# MSS_SPI register map
Vendor: Texas Instruments
Peripheral module from a debugger description file (folder am273).
Registers are 32-bit, access per field, no defined reset value unless marked. A register's access mark holds for its fields unless they carry their own. Offsets are as the file gives them; lines under a group give offsets from that group; [hi:lo] are bit positions; {n}, {i} and the like mark numbered series; 'fields as' and 'values as' point back to an identical list; <NAME> marks a mode.

## MSS_SPI (part 1 of 3)
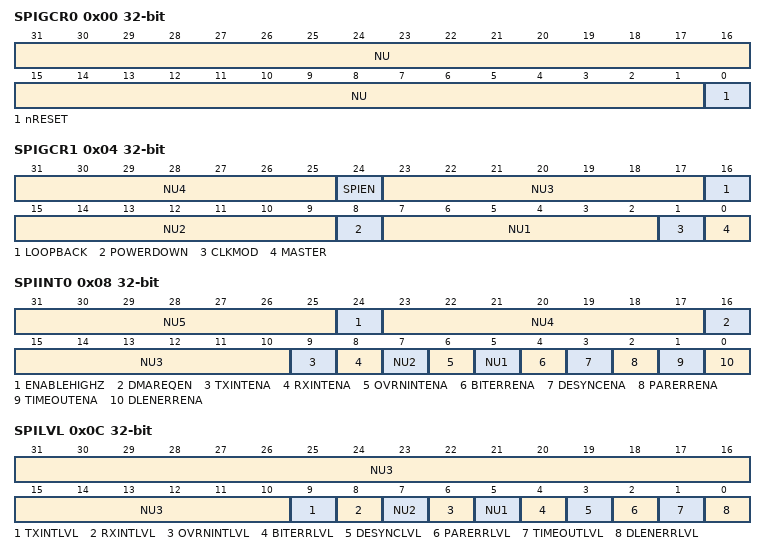
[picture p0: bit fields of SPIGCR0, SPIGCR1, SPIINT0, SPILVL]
0x00 SPIGCR0 — SPI / MibSPI Global Control Register 0
  [31:1] NU ro — Reserved, Reads return ‘0’ and writes have no effect.
  [0] nRESET rw — This is the local reset control for the module. This bit needs to be set to ‘1’ before any operation on SPI / MibSPI can be done. Only after setting this bit to ‘1’, the Auto Initialization of Multibuffer RAM starts. Clearing this bit to ‘0’ will result in all of the control and status register values to return to their default values. 0 = SPI / MibSPI is in reset state 1 = SPI / MibSPI is out of reset state.
0x04 SPIGCR1 — SPI / MibSPI Global control register 1
  [31:25] NU4 ro — Reserved. Reads return ‘0’ and writes have no effect.
  [24] SPIEN rw — SPI enable. This bit enables the SPI/MibSPI transfers. This bit must be set to 1 after all other SPI / MibSPI configuration bits have been written. When SPIEN bit is 0 or cleared to 0, the following SPI/MibSPI registers get forced to their default states (to ‘0’s except for RXEMPTY bit in SPIBUF): - Both TX & RX Shift Registers - The TXDATA fields of SPIDAT0 and SPIDAT1 registers - All the fields of SPIFLG register - Contents of SPIBUF & the internal RXBUF registers 0=SPI / MibSPI is not activated for transfers. 1=Activates SPI / MibSPI
  [23:17] NU3 ro — Reserved. Reads return ‘0’ and writes have no effect.
  [16] LOOPBACK rw — LOOP BACK. Internal loop-back test mode. The internal self-test option can be enabled by setting this bit. If the SPISIMO and SPISOMI pins are configured with SPI functionality, then the SPISIMO pin is internally connected to the SPISOMI pin. The transmit data is looped back as receive data and is stored in the receive field of the concerned buffer. Externally, during loop-back operation, the SPICLK pin outputs an inactive value and SPISOMI remains in high-impedance state. The SPI / MibSPI has to be initialized in master mode before the loop-back can be selected. If the SPI / MibSPI is initialized in slave mode or a data transfer is ongoing, errors may result. 1 =Internal loop-back test mode enabled. 0 =Internal loop-back test mode disabled. This loopback mode can be used only in Master mode. This automatically selects digital loopback path. When this Loopback mode is selected, CLKMOD bit should be set to ‘1’, meaning that SPICLK can only be internal.
  [15:9] NU2 ro — Reserved. Reads return ‘0’ and writes have no effect.
  [8] POWERDOWN rw — POWERDOWN. When active, the SPI / MibSPI state machines enter a powerdown state. 0=MibSPI in active mode 1=MibSPI in powerdown mode
  [7:2] NU1 ro — Reserved. Reads return ‘0’ and writes have no effect.
  [1] CLKMOD rw — CLKMOD. Clock mode Selects either an internal or external clock source. This bit also determines the I/O direction of the SPIENA and SPISCS[7:0] pins in functional mode. 0=Clock is external 1=Clock is internal
  [0] MASTER rw — MASTER: SPISIMO/SPISOMI pin direction determination. Determines the direction of the SPISIMO and SPISOMI pins. This bit determines whether the SPI/MibSPI is in Master mode or Slave mode. This bit also controls the Master-only features like the C2T/T2C counters, C2E/T2E timers, most of the Error conditions specific to Master mode. 0=SPISIMO pin an input, SPISOMI pin an output 1=SPISOMI pin an input, SPISIMO pin an output Note: Although there are two different bits which control the Master/Slave mode functions, only two of their combinations are valid. For compatibility reasons both the bits are retained. For Master mode of operation: MASTER = ‘1’, CLKMOD = ‘1’ For Slave mode of operation: MASTER = ‘0’, CLKMOD = ‘0’ Any other combinations of these two bits may not yield any desirable operation of the module.
0x08 SPIINT0 — SPI / MibSPI Interrupt Enable Register
  [31:25] NU5 ro — Reserved. Reads return ‘0’ and writes have no effect.
  [24] ENABLEHIGHZ rw — SPIENA pin high-z enable. When active, the SPIENA pin (when it is configured as a WAIT functional output signal in a slave SPI) is forced to place it is output in high-z when not driving a low signal. If inactive, then the pin will output both a high and a low signal. 0=SPIENA pin is pulled high when not active. 1=SPIENA pin remains in high-z when not active.
  [23:17] NU4 ro — Reserved. Reads return ‘0’ and writes have no effect.
  [16] DMAREQEN rw — DMA request enable. Enables the DMA request signal to be generated for both receive and transmit channels. Enable DMA REQ only after setting the SPIEN bit to ‘1’. 0=DMA is not used 1=DMA Requests will be generated. A DMA request will be generated on TX DMA REQ line each time a transmit data is copied to the Shift Register either from TXBUF or directly from SPIDAT0/SPIDAT1 writes. A DMA request will be generated on RX DMA REQ line each time a received data is copied to SPIBUF register either from RXBUF or directly from the Shift Register.
  [15:10] NU3 ro — Reserved. Reads return ‘0’ and writes have no effect.
  [9] TXINTENA rw — An interrupt is to be generated everytime data is written to the “Shift Register”, so that a new data can be written to TXBUF. Setting this bit will generate an interrupt if TXINTFLG bit (SPIFLG.9) is set to ‘1’. 0=No interrupt will be generated upon TXINTFLG getting set to ‘1’. 1=Interrupt will be generated upon TXINTFLG getting set to ‘1’. An interrupt request will be generated as soon as this bit is set to ‘1’. By default it will be generated on INT0 line. SPILVL register can be programmed before-hand to change this default.
  [8] RXINTENA rw — An interrupt is to be generated when the RXINTFLAG bit (SPIFLG.8) is set by hardware. Otherwise, no interrupt will be generated. 0=Interrupt will not be generated 1=Interrupt will be generated Both Transmitter Empty & Receiver Full interrupts are valid in SPI or Compatibility mode of MibSPI only. In Multibuffered mode these interrupts will not be generated even if enabled.
  [7] NU2 ro — Reserved. Reads return ‘0’ and writes have no effect.
  [6] OVRNINTENA rw — Overrun interrupt enable. An interrupt is to be generated when the RCVR OVRN flag bit (SPIFLG.6) is set by hardware. Otherwise, no interrupt will be generated. 0=Overrun interrupt will not be generated 1=Overrun interrupt will be generated
  [5] NU1 ro — Reserved. Reads return ‘0’ and writes have no effect.
  [4] BITERRENA rw — Enables interrupt on bit error. 1 =Enables an interrupt on a bit error (BITERR = 1). 0 =No interrupt asserted upon bit error.
  [3] DESYNCENA rw — Enables interrupt on de-synchronized slave. DESYNCENA is used in master mode only. 1 =Enables an interrupt on de-synchronization of the slave (DESYNC = 1). 0 =No interrupt asserted upon de-synchronization error.
  [2] PARERRENA rw — Enables interrupt on parity error. 1 =Enables an interrupt on a parity error (PARITYERR = 1). 0 =No interrupt asserted upon parity error.
  [1] TIMEOUTENA rw — Enables interrupt on ENA signal time-out. 1 =Enables an interrupt on a time-out of the ENA signal (TIMEOUT = 1). 0 =No interrupt asserted upon ENA signal time-out.
  [0] DLENERRENA rw — Data Length Error interrupt Enable. 1 = Enables an interrupt when Data Length Error occurs. 0 = No interrupt is generated upon Data Length Error. A Data Length Error occurs under the following conditions. Master: In a 4-pin with SPIENA mode or 5-pin mode, if the SPIENA pin from the slave is deasserted before the Master has completed its transfer, the Data Length Error is set. That is, if the Character Length counter has not completed counting while SPIENA deassertion is detected, then it means that the Slave has neither received full data from the Master nor has it transmitted complete data. Slave: In a 4-pin with ChipSelects mode or 5-pin mode, if the incoming valid SPISCS pin is de-activated before the Character Length counter completes counting, then Data Length Error is set.
0x0C SPILVL — SPI / MibSPI Interrupt Level Register
  [31:10] NU3 ro — Reserved. Reads return ‘0’ and writes have no effect.
  [9] TXINTLVL rw — Transmit Interrupt Level. 1 =Transmit interrupt is mapped to interrupt line INT1. 0 =Transmit interrupt is mapped to interrupt line INT0.
  [8] RXINTLVL rw — Receive interrupt level. 1 =Receive interrupt is mapped to interrupt line INT1. 0 =Receive interrupt is mapped to interrupt line INT0.
  [7] NU2 ro — Reserved. Reads return ‘0’ and writes have no effect.
  [6] OVRNINTLVL rw — Receive Overrun interrupt level. 1 =Receive Overrun interrupt is mapped to interrupt line INT1. 0 =Receive Overrun interrupt is mapped to interrupt line INT0.
  [5] NU1 ro — Reserved. Reads return ‘0’ and writes have no effect.
  [4] BITERRLVL rw — Bit error interrupt level. 1 =bit error interrupt is mapped to interrupt line INT1. 0 =bit error interrupt is mapped to interrupt line INT0.
  [3] DESYNCLVL rw — De-synchronized slave interrupt level. DESYNCLVL is used in master mode only. 1 =An interrupt due to de-synchronization of the slave (DESYNC = 1) is mapped to interrupt line INT1. 0 =An interrupt due to de-synchronization of the slave (DESYNC = 1) is mapped to interrupt line INT0.
  [2] PARERRLVL rw — Parity error interrupt level. 1 =A parity error interrupt (PARITYERR = 1) is mapped to interrupt line INT1. 0 =A parity error interrupt (PARITYERR = 1) is mapped to interrupt line INT0.
  [1] TIMEOUTLVL rw — SPIENA pin Time-out interrupt level. 1 =An interrupt on a time-out of the ENA signal (TIMEOUT = 1) is mapped to interrupt line INT1. 0 =An interrupt on a time-out of the ENA signal (TIMEOUT = 1) is mapped to interrupt line INT0.
  [0] DLENERRLVL rw — Data Length Error interrupt Enable Level. 1 = An interrupt on Data Length Error is mapped to interrupt line INT1. 0 = An interrupt on Data Length Error is mapped to interrupt line INT0.
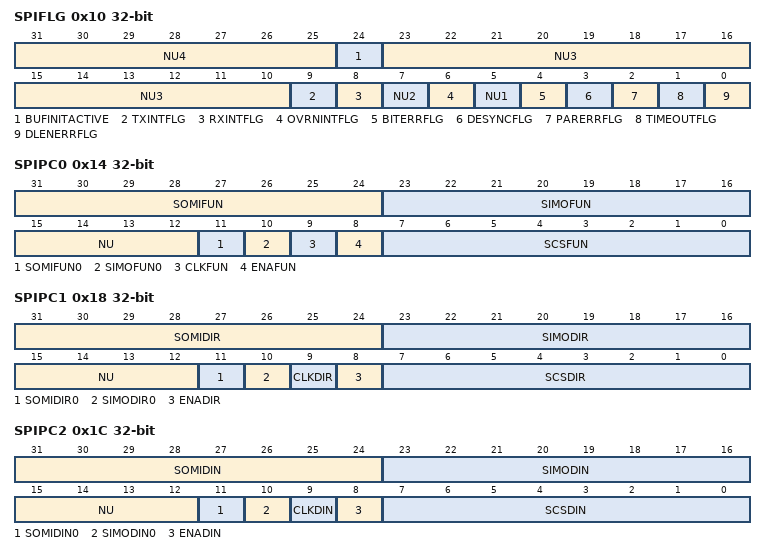
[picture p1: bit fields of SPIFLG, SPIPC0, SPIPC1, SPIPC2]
0x10 SPIFLG access not given — SPI / MibSPI Flag Register
  [31:25] NU4 ro — Reserved. Reads return ‘0’ and writes have no effect.
  [24] BUFINITACTIVE ro — Indicates the status of Multibuffer initialization process. Software should poll this bit to determine if it can proceed with the configuration of Multibuffer mode registers or Multibuffer RAM handling. Refer to Section 3.10.7 for details on Initialization of Multibuffer RAM. 1 = Multibuffer RAM is still being initialized. Do not attempt to write to either Multibuffer RAM or any Multibuffer mode registers. Refer to Section 3.3 for a classification of registers into compatibility mode and Multibuffer mode. 0 = Multibuffer RAM initialization is complete. This bit will show a value of ‘1’ as long as the nRESET bit is ‘0’, but does not really indicate that Buffer initialization is underway. Internal automatic buffer initialization starts only when the nRESET bit is set to ‘1’. For SPI, this bit reads ‘1’ always. For MibSPI, BUF INIT ACTIVE bit will show up as ‘1’ for a maximum of 128/256 (will vary depending upon the actual size of the Multibuffer RAM implemented) VCLK cycles after the nRESET bit in GCR0 is set to ‘1’ and then settle to ‘0’. If Auto Memory Initialization is triggered through System (MEM_AUTO_INIT pulse), then BUF INIT ACTIVE bit will show up as ‘1’ for a maximum of 128/256 (will vary depending upon the actual size of the Multibuffer RAM implemented) VCLK cycles and then settle to ‘0’.
  [23:10] NU3 ro — Reserved. Reads return ‘0’ and writes have no effect.
  [9] TXINTFLG ro — Transmitter Empty Interrupt Flag. Serves as an interrupt flag indicating that Transmit Buffer (TXBUF) is empty and a new data can be written to it. This flag is set when a data is copied to the “Shift Register” either directly or from the TXBUF register. This bit is cleared by one of following ways: Writing a new data to either SPIDAT0 or SPIDAT1 Writing a ‘0’ to SPIEN (SPIGCR1.24) 0= Transmit Buffer is now full. No interrupt pending for Transmitter Empty 1= Transmit Buffer is empty. An interrupt is pending to fill the transmitter.
  [8] RXINTFLG — Receiver Full Interrupt Flag. This flag is set when a word is received and copied into the buffer register (SPIBUF). If RXINTEN is enabled, an interrupt is also generated. During emulation mode, however, a read to the emulation register (SPIEMU) does not clear this flag bit. This bit is cleared under the following ways: Reading the SPIBUF register Reading TGINTVECT0 or TGINTVECT1 register when there is a “Receive Buffer Full” interrupt Writing a ‘1’ to this bit Writing a ‘0’ to SPIEN (SPIGCR1.24) System reset 0= No new received data pending. Receive buffer is Empty. 1= A newly received data is ready to be read. Receive buffer is full. Note: Exception for clearing of RXINT If both SPIBUF and RXBUF (internal buffer) are full, then, reading TGINTVECT0 or TGINTVECT1 register (while it shows 10010) does not clear the RXINTFLG in SPIFLG register. In this case, only way to clear the Interrupt is to read the SPIBUF (twice) and clear all the received data. Note: Side effects of Write Clear to RXINTFLG Clearing RXINTFLG bit by writing a ‘1’ before reading the SPIBUF sets the RXEMPTY bit of the SPIBUF register too. This way, one can ignore a received data. However, if the internal RXBUF is already full, the data from RXBUF will be copied to SPIBUF and RXEMPTY bit will be cleared again. SPIBUF contents should be read first if this situation needs to be avoided.
  [7] NU2 ro — Reserved. Reads return ‘0’ and writes have no effect.
  [6] OVRNINTFLG — Receiver overrun flag. The SPI / MibSPI hardware sets this bit when a receive operation completes before the previous character has been read from the receive buffer. The bit indicates that the last received character has been overwritten and therefore lost. The SPI / MibSPI will generate an interrupt request if this bit is set and the OVRN INTEN bit (SPIINT0.6) is set high. 0 = Overrun condition did not occur 1 = Overrun condition has occurred In SPI or Compatibility mode of MibSPI, this bit is cleared under the following conditions: Reading TGINTVECT0 or TGINTVECT1 register when there is a “Receive Buffer Overrun” interrupt Writing a ‘1’ to OVRNINTFLG in SPIFLG register itself Reading SPIBUF register does not clear this OVRNINTFLG bit. If an RXOVRN interrupt is detected, then the SPIBUF may need to be read twice to get to the Overrun buffer. This is due to the fact that the Overrun will always occur to the internal RXBUF. Each read to the SPIBUF will result in RXBUF contents (if it is full) getting copied to SPIBUF. Note: A special condition under which OVRNINTFLG flag gets set. If both SPIBUF & RXBUF are already full and while another buffer receive is underway, if any errors like TIMEOUT, BITERR & DLEN_ERR occur, then RXOVR in RXBUF & OVRNINTFLG in SPIFLG registers will be set to indicate that the status flags are getting overwritten by the new transfer. This overrun should be treated like a normal Receiver Overrun. In Multibuffer mode of MibSPI, this bit is cleared under the following conditions. Reading the RXOVRN_BUF_ADDR register Writing a ‘1’ to OVRNINTFLG in SPIFLG register itself In Multibuffer mode, if OVRNINTFLG is set, then the address of the buffer which experienced the Overrun is available in RXOVRN_BUF_ADDR.
  [5] NU1 ro — Reserved. Reads return ‘0’ and writes have no effect.
  [4] BITERRFLG — Mismatch of internal transmit data and transmitted data. 1 =A bit error occurred. The SPI / MibSPI samples the signal of the transmit pin (master: SIMO, slave: SOMI) at the receive point (half clock cycle after transmit point). If the sampled value differs from the transmitted value a bit error is detected and the Flag BITERR is set. If BITERRENA is set an interrupt is asserted. A possible reason for a bit error can be a to high bit rate / capacitive load or another master/slave trying to transmit at the same time. 0 =No bit error occurred. This flag can be cleared by one of the following ways. Write a ‘1’ to this bit. Set SPIEN bit to ‘0’.
  [3] DESYNCFLG — De-synchronization of slave device. De-synchronization monitor is active in master mode only. 1 = A slave device is de-synchronized. The master monitors the ENAble signal coming from the slave device and sets the DESYNC flag after the last bit is transmitted plus tT2EDELAY (see Section 8.21). If DESYNCENA is set an interrupt is asserted. De-synchronization can occur if a slave device misses a clock edge coming from the master. 0 =No slave de-synchronization detected. This flag can be cleared by one of the following ways. Write a ‘1’ to this bit. Set SPIEN bit to ‘0’. Note: Inconsistency of Desync flag in SPI/Compatibility mode MibSPI Due to the nature of this Error, under some circumstances it is possible for Desync error detected for the previous buffer to be visible in the current buffer. This is due to the fact that Receive Completion flag/interrupt will be generated when the buffer transfer is completed. But Desync will be detected after the buffer transfer is completed. So, if VBUS master reads the received data quickly when an RXINT is detected, then the status flag may not reflect the correct Desync condition. This inconsistency in Desync flag is valid only in SPI or Compatibility mode of MibSPI. In Multibuffer mode, Desync flag is always guaranteed to be for the current buffer.
  [2] PARERRFLG — Calculated parity differs from received parity bit. 1 =A parity error occurred. If the parity generator is enabled (can be selected individually for each buffer) an even or odd parity bit is added at the end of a data word (see Section 8.23). During reception of the data word the parity generator calculates the reference parity and compares it to the received parity bit. In the event of a mismatch the PARITYERR flag is set and an interrupt is asserted if PARERRENA is set. 0 =No parity error detected. This flag can be cleared by one of the following ways. Write a ‘1’ to this bit. Set SPIEN bit to ‘0’.
  [1] TIMEOUTFLG — Time-out due to non-activation of ENA signal. 1 =An ENA signal time-out occurred. The SPI / MibSPI generates a time-out because the slave hasn’t responded in time by activating the ENA signal after the chip select signal has been activated. If a time-out condition is detected the corresponding chip select is deactivated immediately and the TIMEOUT flag is set. In addition the TIMOUT flag in the status field of the corresponding buffer is set. The transmit request of the concerned buffer is cleared, i.e. the SPI / MibSPI doesn’t re-start a data transfer from this buffer. 0 =No ENA-signal time-out occurred. This flag can be cleared by one of the following ways. Write a ‘1’ to this bit. Set SPIEN bit to ‘0’.
  [0] DLENERRFLG — Data Length Error Flag. 1 = A Data Length Error has occured. 0 = No Data Length Error has occured. This flag can be cleared by one of the following ways. Write a ‘1’ to this bit. Set SPIEN bit to ‘0’. A Data Length Error occurs under the following conditions. Master: In a 4-pin with SPIENA mode or 5-pin mode, if the SPIENA pin from the slave is deasserted before the Master has completed its transfer, the Data Length Error is set. That is, if the Character Length counter has not completed counting while SPIENA pin deassertion is detected, then it means that the Slave has neither received full data from the Master nor has it transmitted complete data. Slave: In a 4-pin with ChipSelects mode or 5-pin mode, if the incoming valid SPISCS pin is de-activated before the Character Length counter completes counting, then Data Length Error is set. Note: Clearing of Transmission Error Flags in SPIBUF during Error conditions Whenever any Transmission Errors (TIMEOUT, BITERR, DLEN_ERR, PARITY_ERR, DESYNC) are detected, and the Error Flag are cleared by writing to the Error bit in SPIFLG register, the corresponding Error flag in SPIBUF does not get cleared. Software needs to read the SPIBUF until it becomes empty before proceeding. This ensures that all the older status bits in SPIBUF are cleared before starting the next transfer.
0x14 SPIPC0 — SPI / MibSPI Pin Control Register 0 (SPIPC0) - SPIFUN Note: Duplicate Control Bits for SIMO0 & SOMI0 Bit 24 is not physically implemented. it is a mirror of Bit11. Any write to Bit 24 will be reflected on Bit11 and when Bit 24 & Bit 11 simultaneously written, the value of Bit11 will control the SOMI pin. Read value of Bit 24 always reflects the Bit 11 value. This is true for the Bit 24 & Bit 11 of all of SPIPC0 to SPIPC9 registers. Same is true for SIMO pin with Bit16 & Bit 10 of SPIPC0 to SPIPC9 registers.
  [31:24] SOMIFUN rw — Slave out, master in function. Determines whether the SPISOMIx pins are to be used as a general-purpose I/O pin or as a SPI / MibSPI functional pin. 0=SPISOMIx pin is a GPIO 1=SPISOMIx pin is a SPI / MibSPI functional pin
  [23:16] SIMOFUN rw — Slave in, master out function. Determines whether the SPISIMOx pin is to be used as a general-purpose I/O pin or as a SPI / MibSPI functional pin. 0=SPISIMOx pin is a GPIO 1=SPISIMOx pin is a SPI / MibSPI functional pin Note: Generic based bit implementation Register bits 31 to 24 and 23 to 16 of SPIPC0 to SPIPC9 are implemented depending upon the generic parameter NUM_PARLL_PINS which determines the number of SIMO/SOMI data lines to be supported. Only if 8 dataline support is selected at the time of logic synthesis, bits 31 to 16 are implemented. Un-implemented bits return ‘0’ upon read and are not writable.
  [15:12] NU ro — Reserved. Reads return ‘0’ and writes have no effect.
  [11] SOMIFUN0 rw — Slave out, master in function. Determines whether the SPISOMI0 pin is to be used as a general-purpose I/O pin or as a SPI / MibSPI functional pin. 0=SPISOMI0 pin is a GPIO 1=SPISOMI0 pin is a SPI / MibSPI functional pin Note: Bit 11 or bit 24 can be used to set the function mode for pin SOMI0. If a 32 bit write is performed, bit 11 will have priority over bit 24.
  [10] SIMOFUN0 rw — Slave in, master out function. Determines whether the SPISIMO0 pin is to be used as a general-purpose I/O pin, or as a SPI / MibSPI functional pin. 0=SPISIMO0 pin is a GPIO 1=SPISIMO0 pin is a SPI / MibSPI functional pin Note: Bit 10 or bit 16 can be used to set the function mode for pin SIMO0. If a 32 bit write is performed, bit 10 will have priority over bit 16.
  [9] CLKFUN rw — SPI / MibSPI clock function. Determines whether the SPICLK pin is to be used as a general-purpose I/O pin, or as a SPI / MibSPI functional pin. 0=SPICLK pin is a GPIO 1=SPICLK pin is a SPI / MibSPI functional pin
  [8] ENAFUN rw — SPIENA function. Determines whether the SPIENA pin is to be used as a general-purpose I/O pin, or as a SPI / MibSPI functional pin. 0=SPIENA pin is a GPIO 1=SPIENA pin is a SPI / MibSPI functional pin
  [7:0] SCSFUN rw — SPISCS[7:0] function. Determines whether the SPISCSx pins are to be used as a general-purpose I/O pins or as SPI functional pins. If the slave SPISCSx pins are in functional mode and receive an inactive high signal, the slave SPI will place it is output in high-z and disable shifting. 0=SPISCSx pin is a GPIO 1=SPISCSx pin is a SPI functional pin Note: Effect of NUM_CS_PINS generic on ChipSelect bits. Actual number of bits implemented in SCSFUN[7:0] will depend upon the NUM_CS_PINS generic set during synthesis. Unimplemented bits will be read-only and will read ‘0’ always.
0x18 SPIPC1 — SPI / MibSPI Pin Control Register 1 (SPIPC1) - SPIDIR
  [31:24] SOMIDIR rw — SPISOMIx direction. Controls the direction of the SPISOMIx pin when it is used as a general-purpose I/O pin. If the SPISOMIx pin is used as a SPI / MibSPI functional pin, the I/O direction is determined by the MASTER bit. 0=SPISOMIx pin is an input 1=SPISOMIx pin is an output
  [23:16] SIMODIR rw — SPISIMOx direction. Controls the direction of the SPISIMOx pin when it is used as a general-purpose I/O pin. If the SPISIMOx pin is used as a SPI / MibSPI functional pin, the I/O direction is determined by the MASTER bit. 0=SPISIMOx pin is an input 1=SPISIMOx pin is an output
  [15:12] NU ro — Reserved. Reads return ‘0’ and writes have no effect.
  [11] SOMIDIR0 rw — SPISOMI0 direction. Controls the direction of the SPISOMI0 pin when it is used as a general-purpose I/O pin. If the SPISOMI0 pin is used as a SPI / MibSPI functional pin, the I/O direction is determined by the MASTER bit. 0=SPISOMI0 pin is an input 1=SPISOMI0 pin is an output Note: Bit 11 or bit 24 can be used to set the direction for pin SOMI0. If a 32 bit write is performed, bit 11 will have priority over bit 24.
  [10] SIMODIR0 rw — SPISIMO0 direction. Controls the direction of the SPISIMO0 pin when it is used as a general-purpose I/O pin. If the SPISIMO0 pin is used as a SPI / MibSPI functional pin, the I/O direction is determined by the MASTER bit. 0=SPISIMO0 pin is an input 1=SPISIMO0 pin is an output Note: Bit 10 or bit 16 can be used to set the direction for pin SIMO0. If a 32 bit write is performed, bit 10 will have priority over bit 16.
  [9] CLKDIR rw — SPICLK direction. Controls the direction of the SPICLK pin when it is used as a general-purpose I/O pin. In functional mode, the I/O direction is determined by the CLKMOD bit. 0=SPICLK pin is an input 1=SPICLK pin is an output
  [8] ENADIR rw — SPIENA direction. Controls the direction of the SPIENA pin when it is used as a general-purpose I/O. If the SPIENA pin is used as a functional pin, then the I/O direction is determined by the CLKMOD bit (SPIGCR1.1). 0=SPIENA pin is an input 1=SPIENA pin is an output
  [7:0] SCSDIR rw — SPISCS[7:0] direction. Controls the direction of the SPISCSx pins when they are used as a general-purpose I/O pin. Each pins could be configured independently from the others If the SPISCSx is used as a SPI functional pin, the I/O direction is determined by the CLKMOD bit (SPIGCR1.1). 0=SPISCSx pin is an input 1=SPISCSx pin is an output Note: Effect of NUM_CS_PINS generic on ChipSelect bits. Actual number of bits implemented in SCSDIR[7:0] will depend upon the NUM_CS_PINS generic set during synthesis. Unimplemented bits will be read-only and will read ‘0’ always.
0x1C SPIPC2 ro — SPI / MibSPI Pin Control Register 2 (SPIPC2) - SPIDIN
  [31:24] SOMIDIN — SPISOMIx data in. Reflects the value of the SPISOMIx pin. 0=Current value on SPISOMIx pin is logic 0. 1=Current value on SPISOMIx pin is logic 1
  [23:16] SIMODIN — SPISIMOx data in. Reflects the value of the SPISIMOx pin. 0=Current value on SPISIMOx pin is logic 0. 1=Current value on SPISIMOx pin is logic 1
  [15:12] NU — Reserved. Reads return ‘0’ and writes have no effect.
  [11] SOMIDIN0 — SPISOMI0 data in. Reflects the value of the SPISOMI0 pin. 0=Current value on SPISOMI0 pin is logic 0. 1=Current value on SPISOMI0 pin is logic 1 Note: Bit 11 or bit 24 can be used to set the direction for pin SOMI0. If a 32 bit write is performed, bit 11 will have priority over bit 24.
  [10] SIMODIN0 — SPISIMO0 data in. Reflects the value of the SPISIMO0 pin. 0=Current value on SPISIMO0 pin is logic 0. 1=Current value on SPISIMO0 pin is logic 1. Note: Bit 10 or bit 16 can be used to set the direction for pin SIMO0. If a 32 bit write is performed, bit 10 will have priority over bit 16.
  [9] CLKDIN — Clock data in. Reflects the value of the SPICLK pin. 0=Current value on SPICLK pin is logic 0. 1=Current value on SPICLK pin is logic 1
  [8] ENADIN — SPIENA data in. Reflects the value of the SPIENA pin. 0=Current value on SPIENA pin is logic 0. 1=Current value on SPIENA pin is logic 1
  [7:0] SCSDIN — SPISCS[7:0] data in. Reflects the value of the SPISCSx pins. 0=Current value on SPISCSx pin is logic 0. 1=Current value on SPISCSx pin is logic 1 Note: Effect of NUM_CS_PINS generic on ChipSelect bits. Actual number of bits implemented in SCSDIN[7:0] will depend upon the NUM_CS_PINS generic set during synthesis. Unimplemented bits will read ‘0’ always.
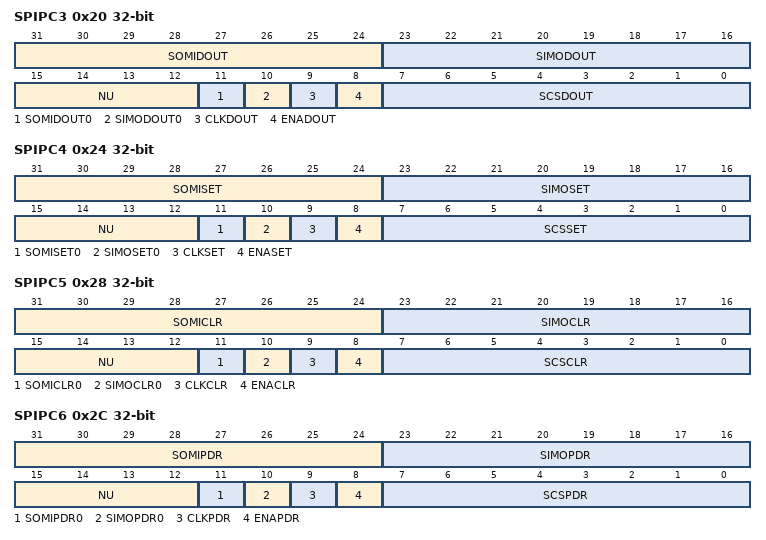
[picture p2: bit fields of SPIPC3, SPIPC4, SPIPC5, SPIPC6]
0x20 SPIPC3 — SPI / MibSPI Pin Control Register 3 (SPIPC3) - SPIDOUT
  [31:24] SOMIDOUT rw — SPISOMIx dataout write. Only active when the SPISOMIx pin is configured as a general-purpose I/O pin and configured as an output pin. The value of this bit indicates the value sent to the pin. 0=Current value on SPISOMIx pin is logic 0. 1=Current value on SPISOMIx pin is logic 1
  [23:16] SIMODOUT rw — SPISIMOx dataout write. Only active when the SPISIMOx pin is configured as a general-purpose I/O pin and configured as an output pin. The value of this bit indicates the value sent to the pin. 0=Current value on SPISIMOx pin is logic 0. 1=Current value on SPISIMOx pin is logic 1
  [15:12] NU ro — Reserved. Reads return ‘0’ and writes have no effect.
  [11] SOMIDOUT0 rw — SPISOMI0 dataout write. Only active when the SPISOMI0 pin is configured as a general-purpose I/O pin and configured as an output pin. The value of this bit indicates the value sent to the pin. 0=Current value on SPISOMI0 pin is logic 0. 1=Current value on SPISOMI0 pin is logic 1. Note: Bit 11 or bit 24 can be used to set the direction for pin SOMI0. If a 32 bit write is performed, bit 11 will have priority over bit 24.
  [10] SIMODOUT0 rw — SPISIMO0 dataout write. Only active when the SPISIMO0 pin is configured as a general-purpose I/O pin and configured as an output pin. The value of this bit indicates the value sent to the pin. 0=Current value on SPISIMO0 pin is logic 0. 1=Current value on SPISIMO0 pin is logic 1. Note: Bit 10 or bit 16 can be used to set the direction for pin SIMO0. If a 32 bit write is performed, bit 10 will have priority over bit 16.
  [9] CLKDOUT rw — SPICLK dataout write. Only active when the SPICLK pin is configured as a general-purpose I/O pin and configured as an output pin. The value of this bit indicates the value sent to the pin. 0=Current value on SPICLK pin is logic 0. 1=Current value on SPICLK pin is logic 1
  [8] ENADOUT rw — SPIENA dataout write. Only active when the SPIENA pin is configured as a general-purpose I/O pin and configured as an output pin. The value of this bit indicates the value sent to the pin. 0=Current value on SPIENA pin is logic 0. 1=Current value on SPIENA pin is logic 1
  [7:0] SCSDOUT rw — SPISCS[7:0] dataout write. Only active when the SPISCSx pins are configured as a general-purpose I/O pins and configured as an output pins. The value of these bit indicates the value sent to the pins. 0=Current value on SPISCSx pin is logic 0. 1=Current value on SPISCSx pin is logic 1 Note: Effect of NUM_CS_PINS generic on ChipSelect bits. Actual number of bits implemented in SCSDOUT[7:0] will depend upon the NUM_CS_PINS generic set during synthesis. Unimplemented bits will be read-only and will read ‘0’ always.
0x24 SPIPC4 — SPI / MibSPI Pin Control Register 4 (SPIPC4) - SPIDSET
  [31:24] SOMISET rw — SPISOMIx dataout set. Only active when the SPISOMIx pin is configured as a general-purpose output pin. A value of ‘1’ written to this bit sets the corresponding SPISOMIDOUTx bit to ‘1’. Write: 0= Has no effect 1= Logic 1 placed on SPISOMIx pin if it is in General Purpose O/P mode Read: 0= Current value on SIMODOUTx is 0. 1= Current value on SOMIDOUTx is 1.
  [23:16] SIMOSET rw — SPISIMOx dataout set. Only active when the SPISIMOx pin is configured as a general-purpose output pin. A value of ‘1’ written to this bit sets the corresponding SPISIMODOUTx bit to ‘1’. Write: 0= Has no effect 1= Logic 1 placed on SPISIMOx pin if it is in General Purpose O/P mode Read: 0= Current value on SIMODOUTx is 0. 1= Current value on SIMODOUTx is 1
  [15:12] NU ro — Reserved. Reads return ‘0’ and writes have no effect.
  [11] SOMISET0 rw — SPISOMI0 dataout set. Only active when the SPISOMI0 pin is configured as a general-purpose output pin. A value of ‘1’ written to this bit sets the corresponding SPISOMIDOUT bit to ‘1’. Write: 0= Has no effect 1= Logic 1 placed on SPISOMI0 pin if it is in General Purpose O/P mode Read: 0= Current value on SOMIDOUT0 is 0. 1= Current value on SOMIDOUT0 is 1. Note: Bit 11 or bit 24 can be used to set the direction for pin SOMI0. If a 32 bit write is performed, bit 11 will have priority over bit 24.
  [10] SIMOSET0 rw — SPISIMO0 dataout set. Only active when the SPISIMO0 pin is configured as a general-purpose output pin. A value of ‘1’ written to this bit sets the corresponding SPISIMODOUT bit to ‘1’. Write: 0= Has no effect 1= Logic 1 placed on SPISIMO0 pin if it is in General Purpose O/P mode Read: 0= Current value on SIMODOUT0 is 0. 1= Current value on SIMODOUT0 is 1. Note: Bit 10 or bit 16 can be used to set the direction for pin SIMO0. If a 32 bit write is performed, bit 10 will have priority over bit 16.
  [9] CLKSET rw — SPICLK dataout set. Only active when the SPICLK pin is configured as a general-purpose output pin. A value of ‘1’ written to this bit sets the corresponding CLKDOUT bit to ‘1’. Write: 0= Has no effect 1= Logic 1 placed on SPICLK pin if it is in General Purpose O/P mode Read: 0= Current value on CLKDOUT pin is logic 0. 1= Current value on CLKDOUT pin is logic 1
  [8] ENASET rw — SPIENA dataout set. Only active when the SPIENA pin is configured as a general-purpose output pin. A value of ‘1’ written to this bit sets the corresponding ENABLEDOUT bit to ‘1’. Write: 0= Has no effect 1= Logic 1 placed on SPIENA pin if it is in General Purpose O/P mode Read: 0= Current value on ENADOUT is 0. 1= Current value on ENADOUT is 1
  [7:0] SCSSET rw — SPISCS[7:0] dataout set. Only active when the SPISCSx pins are configured as a general-purpose output pins. A value of ‘1’ written to these bits set the corresponding SCSDOUT bit to ‘1’. Write: 0= Has no effect 1= Logic 1 placed on SPISCSx pin if it is in General Purpose O/P mode Read: 0= Current value on SCSDOUTx is 0. 1= Current value on SCSDOUTx is 1. Note: Effect of NUM_CS_PINS generic on ChipSelect bits. Actual number of bits implemented in SCSSET[7:0] will depend upon the NUM_CS_PINS generic set during synthesis. Unimplemented bits will be read-only and will read ‘0’ always. Note: Register Read Read of SPIPC4 register gives out contents of the SPIPC3 register.
0x28 SPIPC5 — SPI / MibSPI Pin Control Register 5 (SPIPC5) - SPIDCLR
  [31:24] SOMICLR rw — SPISOMIx dataout clear. Only active when the SPISOMIx pin is configured as a general-purpose output pin. A value of ‘1’ written to this bit clears the corresponding SPISOMIDOUTx bit to ‘0’. Write: 0= Has no effect 1= Logic 0 placed on SPISOMIx pin if it is in General Purpose O/P mode Read: 0= Current value on SOMIDOUTx is 0. 1= Current value on SOMIDOUTx is 1.
  [23:16] SIMOCLR rw — SPISIMOx dataout clear. Only active when the SPISIMOx pin is configured as a general-purpose output pin. A value of ‘1’ written to this bit clears the corresponding SPISIMODOUTx bit to ‘0’. Write: 0= Has no effect 1= Logic 0 placed on SPISIMOx pin if it is in General Purpose O/P mode Read: 0=Current value on SIMODOUTx is 0. 1=Current value on SIMODOUTx is 1.
  [15:12] NU ro — Reserved. Reads return ‘0’ and writes have no effect.
  [11] SOMICLR0 rw — SPISOMI0 dataout clear. Only active when the SPISOMI0 pin is configured as a general-purpose output pin. A value of ‘1’ written to this bit clears the corresponding SPISOMIDOUT bit to ‘0’. Write: 0= Has no effect 1= Logic 0 placed on SPISOMI0 pin if it is in General Purpose O/P mode Read: 0= Current value on SOMIDOUT0 is 0. 1= Current value on SOMIDOUT0 is 1. Note: Bit 11 or bit 24 can be used to set the direction for pin SOMI0. If a 32 bit write is performed, bit 11 will have priority over bit 24.
  [10] SIMOCLR0 rw — SPISIMO0 dataout clear. Only active when the SPISIMO0 pin is configured as a general-purpose output pin. A value of ‘1’ written to this bit clears the corresponding SIMODOUT0 bit to ‘0’. Write: 0= Has no effect 1= Logic 0 placed on SPISIMO0 pin if it is in General Purpose O/P mode Read: 0= Current value on SIMODOUT0 is 0. 1= Current value on SIMODOUT0 is 1. Note: Bit 10 or bit 16 can be used to set the direction for pin SIMO0. If a 32 bit write is performed, bit 10 will have priority over bit 16.
  [9] CLKCLR rw — SPICLK dataout clear. Only active when the SPICLK pin is configured as a general-purpose output pin. A value of ‘1’ written to this bit clears the corresponding CLKDOUT bit to ‘0’. Write: 0= Has no effect 1= Logic 0 placed on SPICLK pin if it is in General Purpose O/P mode Read: 0= Current value on CLKDOUT is 0. 1= Current value on CLKDOUT is 1.
  [8] ENACLR rw — SPIENA dataout clear. Only active when the SPIENA pin is configured as a general-purpose output pin. A value of ‘1’ written to this bit clears the corresponding ENABLEDOUT bit to ‘0’. Write: 0= Has no effect 1= Logic 0 placed on SPIENA pin if it is in General Purpose O/P mode Read: 0= Current value on ENADOUT is 0. 1= Current value on ENADOUT is 1.
  [7:0] SCSCLR rw — SPISCS[7:0] dataout clear. Only active when the SPISCSx pins are configured as a general-purpose output pins. A value of ‘1’ written to this bit clears the corresponding SCSDOUT bit to ‘0.. Write: 0= Has no effect 1= Logic 0 placed on SPISCSx pin if it is in General Purpose O/P mode Read: 0= Current value on SCSDOUTx is 0. 1= Current value on SCSDOUTx is 1 Note: Effect of NUM_CS_PINS generic on ChipSelect bits. Actual number of bits implemented in SCSCLR[7:0] will depend upon the NUM_CS_PINS generic set during synthesis. Unimplemented bits will be read-only and will read ‘0’ always. Note: Register Read Read of SPIPC5 register gives out contents of the SPIPC3 register.
0x2C SPIPC6 — SPI / MibSPI Pin Control Register 6 (SPIPC6) - SPIPDR
  [31:24] SOMIPDR rw — SPISOMIx Open drain enable Enables Open drain capability for the pin SOMIx if the following conditions are met. SOMIDIRx = 1 (SPISOMI0 pin configured in GPIO mode as output pin) SOMIDOUTx = 1 0 = Output value on SPISOMIx pin is logic ‘1’ 1 = Output pin SPISOMIx is Tri-stated
  [23:16] SIMOPDR rw — SPISIMOx Open drain enable Enables Open drain capability for the pin SPISIMOx if the following conditions are met. SIMODIRx = 1 (SPISIMOx pin configured in GPIO mode as output pin) SIMODOUTx = 1 0 = Output value on SPISIMOx pin is logic ‘1’ 1 = Output pin SPISIMOx is Tri-stated
  [15:12] NU ro — Reserved. Reads return ‘0’ and writes have no effect.
  [11] SOMIPDR0 rw — SPISOMI0 Open drain enable Enables Open drain capability for the pin SPISOMI if the following conditions are met. SOMIDIR0 = 1 (SPISOMI0 pin configured in GPIO mode as output pin) SOMIDOUT0 = 1 0 = Output value on SPISOMI0 pin is logic ‘1’ 1 = Output pin SPISOMI0 is Tri-stated Note: Bit 11 or bit 24 can be used to set the direction for pin SPISOMI0. If a 32 bit write is performed, bit 11 will have priority over bit 24.
  [10] SIMOPDR0 rw — SPISIMO0 Open drain enable Enables Open drain capability for the pin SPISIMO0 if the following conditions are met. SIMODIR0 = 1 (SPISIMO pin configured in GPIO mode as output pin) SIMODOUT0 = 1 0 = Output value on SPISIMO0 pin is logic ‘1’ 1 = Output pin SPISIMO0 is Tri-stated Note: Bit 10 or bit 16 can be used to set the direction for pin SPISIMO0. If a 32 bit write is performed, bit 10 will have priority over bit 16.
  [9] CLKPDR rw — SPICLK Open drain enable Enables Open drain capability for the pin CLK if the following conditions are met. CLKDIR = 1 (SPICLK pin configured in GPIO mode as output pin) CLKDOUT = 1 0 = Output value on SPICLK pin is logic ‘1’ 1 = Output pin SPICLK is Tri-stated
  [8] ENAPDR rw — SPIENA Open drain enable Enables Open drain capability for the pin SPIENA if the following conditions are met. ENABLEDIR = 1 (SPIENA pin configured in GPIO mode as output pin) ENABLEDOUT = 1 0 = Output value on SPIENA pin is logic ‘1’ 1 = Output pin SPIENA is Tri-stated
  [7:0] SCSPDR rw — SPISCSx Open drain enable Enables Open drain capability for the pin SPISCSx if the following conditions are met. SCSDIRx = 1 (SPISCS pin configured in GPIO mode as output pin) SCSDOUTx = 1 0 = Output value on SPISCSx pin is logic ‘1’ 1 = Output pin SPISCSx is Tri-stated Note: Effect of NUM_CS_PINS generic on ChipSelect bits. Actual number of bits implemented in SCSPDR[7:0] will depend upon the NUM_CS_PINS generic set during synthesis. Unimplemented bits will be read-only and will read ‘0’ always.
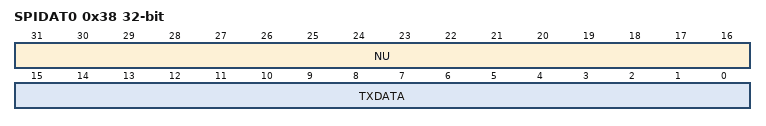
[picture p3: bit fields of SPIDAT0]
0x38 SPIDAT0 — SPI / MibSPI Transmit Data Register 0 Note: Accessibility of SPIDAT0 The SPIDAT0 register is not accessible in Multibuffer Mode of MibSPI. It is only accessible in compatibility mode.
  [31:16] NU ro — Reserved. Reads return ‘0’ and writes have no effect.
  [15:0] TXDATA rw — SPI / MibSPI Transmit Data. When written, these bits will be copied to the Shift Register if it is empty. If the Shift Register is not empty, the TXBUF will hold the written values. SPIEN (SPICGR1.24) must be set to 1 before this register can be written to. Writing a 0 to the SPIEN register forces the lower 16 bits of the SPIDAT0 register to 0x00. When this register is read, contents of internal buffer register TXBUF which holds the latest written data will be returned. As the data is shifted out from either the MSB or the LSB of Transmit Shift Register depending upon SHIFTDIR bit (SPIFMTx.20). Simultaneously, the received bit will be shifted into the Receive Shift Register either through LSB or MSB depending upon SHIFTDIR bit. This allows the concurrent transmission and reception of data. Note: Irrespective of the character length, the Transmit data should be right justified before writing to SPIDAT0 register. The default Data Format Control register for SPIDAT0 is SPIFMT0. However it is possible to reprogram the DFSEL[1:0] fields of SPIDAT1 prior to using SPIDAT0, to select a different SPIFMTx register.
